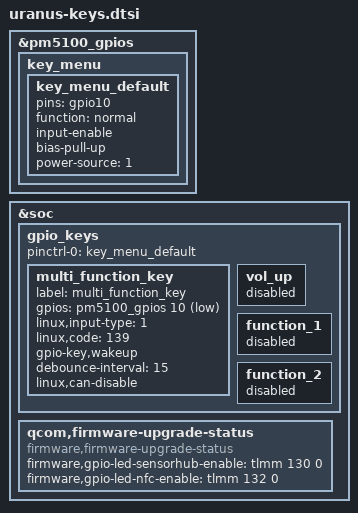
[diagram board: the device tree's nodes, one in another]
#include <dt-bindings/gpio/gpio.h>
#include <dt-bindings/input/input.h>
#include <dt-bindings/iio/qti_power_supply_iio.h>
&pm5100_gpios {
	key_menu {
		key_menu_default: key_menu_default {
			pins = "gpio10";
			function = "normal";
			input-enable;
			bias-pull-up;
			power-source = <1>;
		};
	};
};
&soc {
	gpio_keys {
		pinctrl-0 = <&key_menu_default>;
		multi_function_key {
			label = "multi_function_key";
			gpios = <&pm5100_gpios 10 GPIO_ACTIVE_LOW>;
			linux,input-type = <1>;
			linux,code = <139>; /*KEY_MENU*/
			gpio-key,wakeup;
			debounce-interval = <15>;
			linux,can-disable;
		};
		vol_up {
			status = "disabled";
		};
		function_1 {
			status = "disabled";
		};
		function_2 {
			status = "disabled";
		};
	};

        qcom,firmware-upgrade-status {
            compatible = "firmware,firmware-upgrade-status";

            firmware,gpio-led-sensorhub-enable = <&tlmm 130 0>;
            firmware,gpio-led-nfc-enable = <&tlmm 132 0>;
            status = "ok";
        };
};
